# SAM9X75D1M device description
Architecture: ARM926EJ-S; Family: SAM9; Series: SAM9X7
Registers are 32-bit, read-write, reset 0x0 unless marked. A register's access mark holds for its fields unless they carry their own. Offsets are from the block's base; [hi:lo] are bit positions; {n}, {i} and the like mark numbered series.

## DSI — MIPI DSI Host
0x00 DSI_VERSION ro reset not defined — This register contains the version of the DSI host controller.
  [31:0] VERSION — This field indicates the version of the DWC_mipi_dsi_host.
0x04 DSI_PWR_UP reset not defined — This register controls the power up of the core.
  [0] SHUTDOWNZ — This bit configures the core either to power up or to reset. - 0: Reset - 1: Power-up
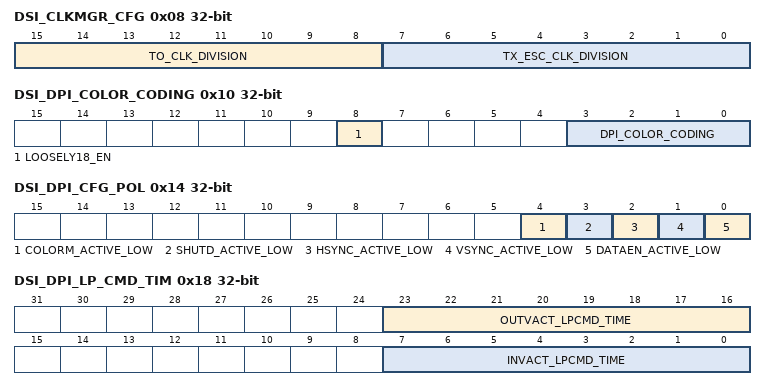
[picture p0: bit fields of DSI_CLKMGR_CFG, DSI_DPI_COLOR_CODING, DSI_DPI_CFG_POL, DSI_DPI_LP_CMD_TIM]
0x08 DSI_CLKMGR_CFG reset not defined — This register configures the factor for internal dividers to divide lanebyteclk for timeout purposes.
  [15:8] TO_CLK_DIVISION — This field indicates the division factor for the Time Out clock used as the timing unit in the configuration of HS to LP and LP to HS transition error.
  [7:0] TX_ESC_CLK_DIVISION — This field indicates the division factor for the TX Escape clock source (lanebyteclk). The values 0 and 1 stop the TX_ESC clock generation.
0x0C DSI_DPI_VCID reset not defined — This register configures the Virtual Channel ID for DPI traffic.
  [1:0] DPI_VCID — This field configures the DPI virtual channel id that is indexed to the Video mode packets.
0x10 DSI_DPI_COLOR_CODING reset not defined — This register configures DPI color coding.
  [8] LOOSELY18_EN — When set to 1, this bit activates loosely packed variant to 18-bit configurations.
  [3:0] DPI_COLOR_CODING — This field configures the DPI color coding as follows: - 0000: 16-bit configuration 1 - 0001: 16-bit configuration 2 - 0010: 16-bit configuration 3 - 0011: 18-bit configuration 1 - 0100: 18-bit configuration 2 - 0101: 24-bit - 0110: 20-bit YCbCr 4:2:2 loosely packed - 0111: 24-bit YCbCr 4:2:2 - 1000: 16-bit YCbCr 4:2:2 - 1001: 30-bit - 1010: 36-bit - 1011: 12-bit YCbCr 4:2:0 - 11xx: DSC24 compressed Data If the eDPI interface is chosen and currently works in the Command mode (cmd_video_mode = 1), then: - 0000: 16-bit configuration 1 - 0001: 16-bit configuration 2 - 0010: 16-bit configuration 3 - 0011: 18-bit configuration 1 - 0100: 18-bit configuration 2 - 0101-0111: 24-bit - 1Xxx: DSC24 compressed Data
0x14 DSI_DPI_CFG_POL reset not defined — This register configures the polarity of DPI signals.
  [4] COLORM_ACTIVE_LOW — When set to 1, this bit configures the color mode pin (dpicolorm) as active low.
  [3] SHUTD_ACTIVE_LOW — When set to 1, this bit configures the shutdown pin (dpishutdn) as active low.
  [2] HSYNC_ACTIVE_LOW — When set to 1, this bit configures the horizontal synchronism pin (dpihsync) as active low.
  [1] VSYNC_ACTIVE_LOW — When set to 1, this bit configures the vertical synchronism pin (dpivsync) as active low.
  [0] DATAEN_ACTIVE_LOW — When set to 1, this bit configures the data enable pin (dpidataen) as active low.
0x18 DSI_DPI_LP_CMD_TIM reset not defined — This register configures the timing for low-power commands sent while in video mode.
  [23:16] OUTVACT_LPCMD_TIME — This field is used for the transmission of commands in low-power mode. It defines the size, in bytes, of the largest packet that can fit in a line during the VSA, VBP, and VFP regions.
  [7:0] INVACT_LPCMD_TIME — This field is used for the transmission of commands in low-power mode. It defines the size, in bytes, of the largest packet that can fit in a line during the VACT region.
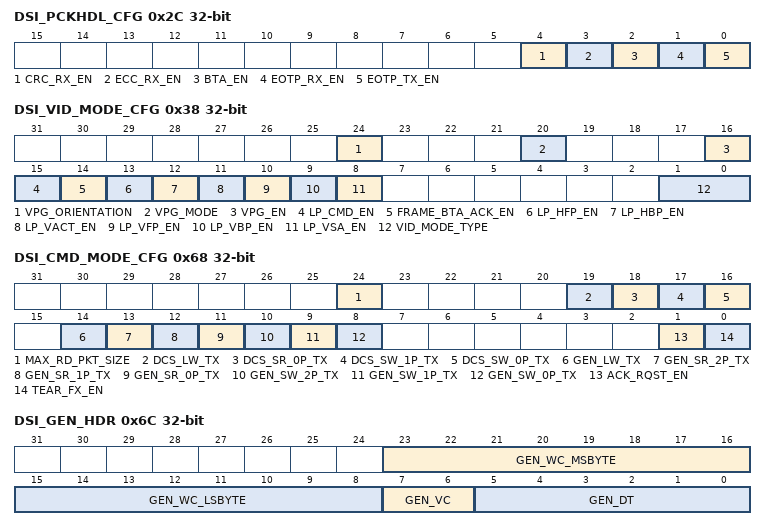
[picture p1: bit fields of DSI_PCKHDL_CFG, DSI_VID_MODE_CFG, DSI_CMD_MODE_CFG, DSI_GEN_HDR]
0x2C DSI_PCKHDL_CFG reset not defined — This register configures how EoTp, BTA, CRC and ECC are to be used, to meet peripheral's characteristics
  [4] CRC_RX_EN — When set to 1, this bit enables the CRC reception and error reporting.
  [3] ECC_RX_EN — When set to 1, this bit enables the ECC reception, error correction, and reporting.
  [2] BTA_EN — When set to 1, this bit enables the Bus Turn-Around (BTA) request.
  [1] EOTP_RX_EN — When set to 1, this bit enables the EoTp reception.
  [0] EOTP_TX_EN — When set to 1, this bit enables the EoTp transmission.
0x30 DSI_GEN_VCID reset not defined — This register configures the Virtual Channel ID of READ responses to store and return to Generic interface.
  [1:0] GEN_VCID_RX — This field indicates the Generic interface read-back virtual channel identification.
0x34 DSI_MODE_CFG reset not defined — This register configures the mode of operation between Video or Command Mode. (Commands can still be sent while in video mode.)
  [0] CMD_VIDEO_MODE — This bit configuers the operation mode: - 0: video mode - 1: command mode
0x38 DSI_VID_MODE_CFG reset not defined — This register configures several aspects of Video mode operation, the transmission mode, switching to Low-Power in the middle of a frame, enabling acknowledge and whether to send commands in Low-Power.
  [24] VPG_ORIENTATION — This field indicates the color bar orientation as follows: - 0: Vertical mode - 1: Horizontal mode
  [20] VPG_MODE — This field is to select the pattern: - 0: Color bar (horizontal or vertical) - 1: BERpattern (vertical only)
  [16] VPG_EN — When set to 1, this bit enables the video mode pattern generator.
  [15] LP_CMD_EN — When set to 1, this bit enables the command transmission only in low-power mode.
  [14] FRAME_BTA_ACK_EN — When set to 1, this bit enables the request for an acknowledge response at the end of a frame.
  [13] LP_HFP_EN — When set to 1, this bit enables the return to low-power inside the HFP period when timing allows.
  [12] LP_HBP_EN — When set to 1, this bit enables the return to low-power inside the HBP period when timing allows.
  [11] LP_VACT_EN — When set to 1, this bit enables the return to low-power inside the VACT period when timing allows.
  [10] LP_VFP_EN — When set to 1, this bit enables the return to low-power inside the VFP period when timing allows.
  [9] LP_VBP_EN — When set to 1, this bit enables the return to low-power inside the VBP period when timing allows.
  [8] LP_VSA_EN — When set to 1, this bit enables the return to low-power inside the VSA period when timing allows.
  [1:0] VID_MODE_TYPE — This field indicates the video mode transmission type as follows: - 00: Non-burst with sync pulses - 01: Non-burst with sync events - 10 and 11: Burst mode
0x3C DSI_VID_PKT_SIZE reset not defined — This register configures the video packet size.
  [13:0] VID_PKT_SIZE — This field configures the number of pixels in a single video packet. - For 18-bit not loosely packed data types, this number must be a multiple of 4. - For YCbCr data types, it must be a multiple of 2, as described in the DSI specification. - For DSC24, this field configures the number of Bytes. Note that when using slices (i.e chunks) the minimum size packet size must be 3.
0x40 DSI_VID_NUM_CHUNKS reset not defined — This register configures the number of chunks to use. The data in each chunk has the size provided by VID_PKT_SIZE.
  [12:0] VID_NUM_CHUNKS — This register configures the number of chunks to be transmitted during a Line period (a chunk is pair made of a video packet and a null packet). If set to 0 or 1, video line is still transmitted in a single packet. If set to 1 that packet is part of a chunk, meaning that a null packet follows it (if vid_null_size>0). Otherwise, multiple chunks are used to transmit each video line.
0x44 DSI_VID_NULL_SIZE reset not defined — This register configures the size of null packets.
  [12:0] VID_NULL_SIZE — This register configures the number of bytes inside a null packet. Setting to 0 disables null packets.
0x48 DSI_VID_HSA_TIME reset not defined — This register configures the video HSA time.
  [11:0] VID_HSA_TIME — This field configures the Horizontal Synchronism Active period in lane byte clock cycles.
0x4C DSI_VID_HBP_TIME reset not defined — This register configures the video HBP time.
  [11:0] VID_HBP_TIME — This field configures the Horizontal Back Porch period in lane byte clock cycles.
0x50 DSI_VID_HLINE_TIME reset not defined — This register configures the overall time for each video line.
  [14:0] VID_HLINE_TIME — This field configures the size of the total line time (HSA+HBP+HACT+HFP) counted in lane byte clock cycles.
0x54 DSI_VID_VSA_LINES reset not defined — This register configures the VSA period.
  [9:0] VSA_LINES — This field configures the Vertical Synchronism Active period measured in number of horizontal lines.
0x58 DSI_VID_VBP_LINES reset not defined — This register configures the VBP period.
  [9:0] VBP_LINES — This field configures the Vertical Back Porch period measured in number of horizontal lines.
0x5C DSI_VID_VFP_LINES reset not defined — This register configures the VFP period.
  [9:0] VFP_LINES — This field configures the Vertical Front Porch period measured in number of horizontal lines.
0x60 DSI_VID_VACTIVE_LINES reset not defined — This register configures the vertical resolution of video.
  [13:0] V_ACTIVE_LINES — This field configures the Vertical Active period measured in number of horizontal lines.
0x68 DSI_CMD_MODE_CFG reset not defined — This register configures several aspect of command mode operation, tearing effect, acknowledge for each packet and the speed mode to transmit each Data Type related to commands.
  [24] MAX_RD_PKT_SIZE — This bit configures the maximum read packet size command transmission type: - 0: High-speed - 1: Low-power
  [19] DCS_LW_TX — This bit configures the DCS long write packet command transmission type: - 0: High-speed - 1: Low-power
  [18] DCS_SR_0P_TX — This bit configures the DCS short read packet with zero parameter command transmission type: - 0: High-speed - 1: Low-power
  [17] DCS_SW_1P_TX — This bit configures the DCS short write packet with one parameter command transmission type: - 0: High-speed - 1: Low-power
  [16] DCS_SW_0P_TX — This bit configures the DCS short write packet with zero parameter command transmission type: - 0: High-speed - 1: Low-power
  [14] GEN_LW_TX — This bit configures the Generic long write packet command transmission type: - 0: High-speed - 1: Low-power
  [13] GEN_SR_2P_TX — This bit configures the Generic short read packet with two parameters command transmission type: - 0: High-speed - 1: Low-power
  [12] GEN_SR_1P_TX — This bit configures the Generic short read packet with one parameter command transmission type: - 0: High-speed - 1: Low-power
  [11] GEN_SR_0P_TX — This bit configures the Generic short read packet with zero parameter command transmission type: - 0: High-speed - 1: Low-power
  [10] GEN_SW_2P_TX — This bit configures the Generic short write packet with two parameters command transmission type: - 0: High-speed - 1: Low-power
  [9] GEN_SW_1P_TX — This bit configures the Generic short write packet with one parameter command transmission type: - 0: High-speed - 1: Low-power
  [8] GEN_SW_0P_TX — This bit configures the Generic short write packet with zero parameter command transmission type: - 0: High-speed - 1: Low-power
  [1] ACK_RQST_EN — When set to 1, this bit enables the acknowledge request after each packet transmission.
  [0] TEAR_FX_EN — When set to 1, this bit enables the tearing effect acknowledge request.
0x6C DSI_GEN_HDR reset not defined — This register sets the header for new packets sent using the Generic interface.
  [23:16] GEN_WC_MSBYTE — This field configures the most significant byte of the header packet's word count for long packets or data 1 for short packets.
  [15:8] GEN_WC_LSBYTE — This field configures the least significant byte of the header packet's Word count for long packets or data 0 for short packets.
  [7:6] GEN_VC — This field configures the Virtual Channel ID of the header packet.
  [5:0] GEN_DT — This field configures the packet Data Type of the header packet.
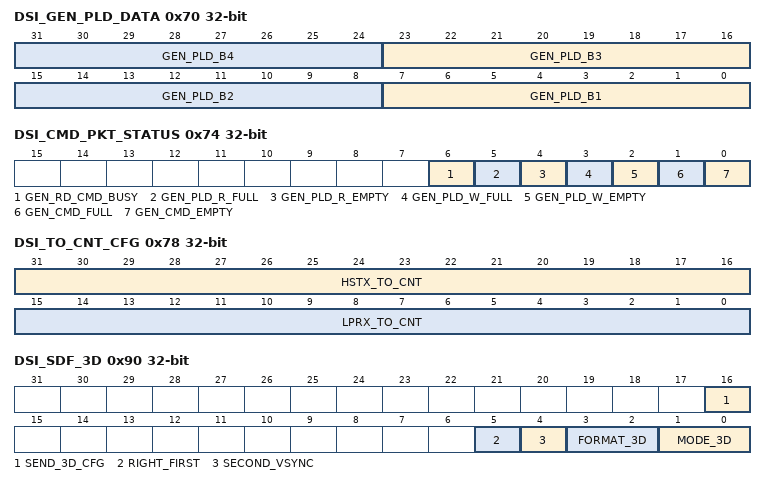
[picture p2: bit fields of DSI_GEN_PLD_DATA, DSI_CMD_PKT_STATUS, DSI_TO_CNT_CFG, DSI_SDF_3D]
0x70 DSI_GEN_PLD_DATA reset not defined — This register sets the payload for packets sent using the Generic interface and, when read, returns the contents of READ responses from the peripheral.
  [8n-1:8n-8] GEN_PLD_B{n} (n=1..4) — This field indicates byte {n} of the packet payload.
0x74 DSI_CMD_PKT_STATUS ro reset not defined — This register configures contains information about the status of FIFOs related to DBI and Generic interface.
  [6] GEN_RD_CMD_BUSY — This bit is set when a read command is issued and cleared when the entire response is stored in the FIFO for GENERIC interface.
  [5] GEN_PLD_R_FULL — This bit indicates the full status of the generic read payload FIFO.
  [4] GEN_PLD_R_EMPTY — This bit indicates the empty status of the generic read payload FIFO.
  [3] GEN_PLD_W_FULL — This bit indicates the full status of the generic write payload FIFO.
  [2] GEN_PLD_W_EMPTY — This bit indicates the empty status of the generic write payload FIFO.
  [1] GEN_CMD_FULL — This bit indicates the full status of the generic command FIFO.
  [0] GEN_CMD_EMPTY — This bit indicates the empty status of the generic command FIFO.
0x78 DSI_TO_CNT_CFG reset not defined — This register configures counters that trigger timeout errors. These are used to warn the system of a failure, through an interrupt, and restart the core in case of unexpected situations that cause deadlock conditions.
  [31:16] HSTX_TO_CNT — This field configures the timeout counter that triggers a high-speed transmission timeout contention detection (measured in TO_CLK_DIVISION cycles). If using non-burst mode and there is not sufficient time to switch from HS to LP and back in the period which is from one line data finishing to the next line sync start, the DSI link will return LP state once per frame, then you should configure the TO_CLK_DIVISION and hstx_to_cnt to satisfy the formula below: hstx_to_cnt * lanebyteclkperiod * TO_CLK_DIVISION >= the time of one FRAME data transmission * (1 + 10%) In burst mode, RGB pixel packets are time-compressed, leaving more time during a scan line. So if in burst mode and there is sufficient time to switch from HS to LP and back in the period of time from one line data finishing to the next line sync start, the DSI link can return LP mode and back in this time interval to save power. If you choose so, you should configure the TO_CLK_DIVISION and hstx_to_cnt to satisfy the formula below: hstx_to_cnt * lanebyteclkperiod * TO_CLK_DIVISION >= the time of one LINE data transmission * (1 + 10%)
  [15:0] LPRX_TO_CNT — This field configures the timeout counter that triggers a low-power reception timeout contention detection (measured in TO_CLK_DIVISION cycles).
0x7C DSI_HS_RD_TO_CNT reset not defined — This register configures the Peripheral Response timeout after High-Speed Read operations.
  [15:0] HS_RD_TO_CNT — This field sets a period for which DWC_mipi_dsi_host keeps the link still, after sending a High-Speed Read operation. This period is measured in cycles of lanebyteclk, starts to count when the D-PHY enters stop state and causes no interrupts.
0x80 DSI_LP_RD_TO_CNT reset not defined — This register configures the Peripheral Response timeout after Low-Power Read operations.
  [15:0] LP_RD_TO_CNT — This field sets a period for which DWC_mipi_dsi_host keeps the link still, after sending a Low-Power Read operation. This period is measured in cycles of lanebyteclk, starts to count when the D-PHY enters stop state and causes no interrupts.
0x84 DSI_HS_WR_TO_CNT reset not defined — This register configures the Peripheral Response timeout after High-Speed Write operations.
  [15:0] HS_WR_TO_CNT — This field sets a period for which DWC_mipi_dsi_host keeps the link still, after sending a High-Speed Write operation. This period is measured in cycles of lanebyteclk, starts to count when the D-PHY enters stop state and causes no interrupts.
0x88 DSI_LP_WR_TO_CNT reset not defined — This register configures the Peripheral Response timeout after Low-Power Write operations.
  [15:0] LP_WR_TO_CNT — This field sets a period for which DWC_mipi_dsi_host keeps the link still, after sending a Low-Power Write operation. This period is measured in cycles of lanebyteclk, starts to count when the D-PHY enters stop state and causes no interrupts.
0x8C DSI_BTA_TO_CNT reset not defined — This register configures the Peripheral Response timeout after Bus Turnaround completion.
  [15:0] BTA_TO_CNT — This field sets a period for which DWC_mipi_dsi_host keeps the link still, after completing a Bus Turnaround. This period is measured in cycles of lanebyteclk, starts to count when the D-PHY enters stop state and causes no interrupts.
0x90 DSI_SDF_3D reset not defined — This register stores 3D control information for VSS packets in video mode.
  [16] SEND_3D_CFG — When set, causes the next VSS packet to include 3D control payload in every VSS packet.
  [5] RIGHT_FIRST — This bit defines the left/right order: - 0: left eye is sent first, then right eye - 1: right eye data is sent first, then left eye
  [4] SECOND_VSYNC — This field defines whether there is a second VSYNC pulse between Left and Right Images, when 3D Image Format is Frame-based: - 0: No sync pulses between left and right data. - 1: Sync pulse (HSYNC, VSYNC, blanking) between left and right data.
  [3:2] FORMAT_3D — This field defines 3D Image Format: - 00: Line (alternating lines of left and right data). - 01: Frame (alternating frames of left and right data). - 10: Pixel (alternating pixels of left and right data). - 11: Reserved
  [1:0] MODE_3D — This field defines 3D Mode On/Off and Display Orientation: - 00: 3D Mode Off (2D Mode On). - 01: 3D Mode On, Portrait Orientation. - 10: 3D Mode On, Landscape Orientation. - 11: Reserved.
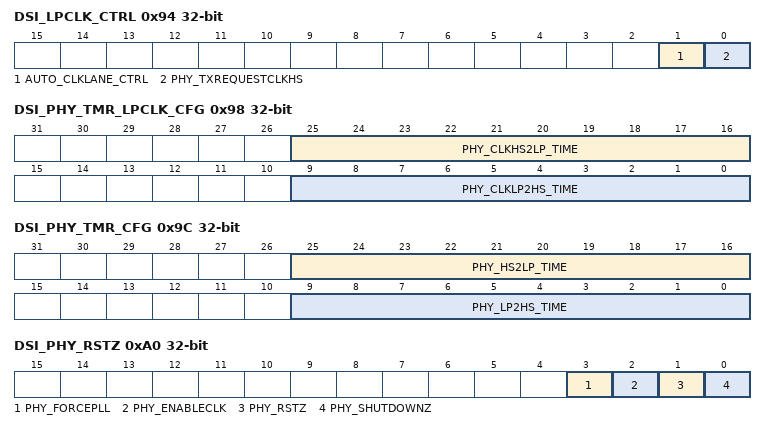
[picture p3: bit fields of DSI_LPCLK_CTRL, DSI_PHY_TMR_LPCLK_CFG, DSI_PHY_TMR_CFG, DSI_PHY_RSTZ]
0x94 DSI_LPCLK_CTRL reset not defined — This register configures the possibility for using non continuous clock in the clock lane.
  [1] AUTO_CLKLANE_CTRL — This bit enables the automatic mechanism to stop providing clock in the clock lane when time allows.
  [0] PHY_TXREQUESTCLKHS — This bit controls the D-PHY PPI txrequestclkhs signal.
0x98 DSI_PHY_TMR_LPCLK_CFG reset not defined — This register sets the time that DWC_mipi_dsi_host assumes in calculations for the clock lane to switch between High-Speed and Low-Power.
  [25:16] PHY_CLKHS2LP_TIME — This field configures the maximum time that the D-PHY clock lane takes to go from high-speed to low-power transmission measured in lane byte clock cycles.
  [9:0] PHY_CLKLP2HS_TIME — This field configures the maximum time that the D-PHY clock lane takes to go from low-power to high-speed transmission measured in lane byte clock cycles.
0x9C DSI_PHY_TMR_CFG reset not defined — This register sets the time that DWC_mipi_dsi_host assumes in calculations for the data lanes to switch between High-Speed and Low-Power.
  [25:16] PHY_HS2LP_TIME — This field configures the maximum time that the D-PHY data lanes take to go from high-speed to low-power transmission measured in lane byte clock cycles.
  [9:0] PHY_LP2HS_TIME — This field configures the maximum time that the D-PHY data lanes take to go from low-power to high-speed transmission measured in lane byte clock cycles.
0xA0 DSI_PHY_RSTZ reset not defined — This register controls resets and the PLL of the D-PHY.
  [3] PHY_FORCEPLL — When the D-PHY is in ULPS, this bit enables the D-PHY PLL.
  [2] PHY_ENABLECLK — When set to 1, this bit enables the D-PHY Clock Lane Module.
  [1] PHY_RSTZ — When set to 0, this bit places the digital section of the D-PHY in the reset state.
  [0] PHY_SHUTDOWNZ — When set to 0, this bit places the complete D-PHY macro in power-down state.
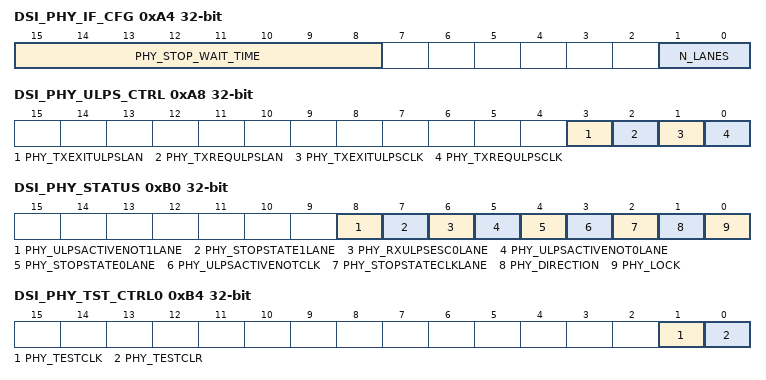
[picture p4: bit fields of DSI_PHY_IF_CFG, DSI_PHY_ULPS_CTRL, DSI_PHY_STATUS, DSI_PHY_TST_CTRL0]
0xA4 DSI_PHY_IF_CFG reset not defined — This register configures the number of active lanes and the minimum time to remain in stop state.
  [15:8] PHY_STOP_WAIT_TIME — This field configures the minimum wait period to request a highspeed transmission after the Stop state.
  [1:0] N_LANES — This field configures the number of active data lanes: - 00: One data lane (ane 0) - 01: Two data lanes (lanes 0 and 1) - 10: Three data lanes (lanes 0, 1, and 2) - 11: Four data lanes (lanes 0, 1, 2, and 3)
0xA8 DSI_PHY_ULPS_CTRL reset not defined — This register configures entering and leaving ULPS in the D-PHY.
  [3] PHY_TXEXITULPSLAN — ULPS mode Exit on all active data lanes.
  [2] PHY_TXREQULPSLAN — ULPS mode Request on all active data lanes.
  [1] PHY_TXEXITULPSCLK — ULPS mode Exit on clock lane.
  [0] PHY_TXREQULPSCLK — ULPS mode Request on clock lane.
0xAC DSI_PHY_TX_TRIGGERS reset not defined — This register configures the pins that activate triggers in the D-PHY.
  [3:0] PHY_TX_TRIGGERS — This field controls the trigger transmissions.
0xB0 DSI_PHY_STATUS ro reset not defined — This register contains information about the status of the D-PHY.
  [8] PHY_ULPSACTIVENOT1LANE — This bit indicates the status of ulpsactivenot1lane D-PHY signal.
  [7] PHY_STOPSTATE1LANE — This bit indicates the status of phystopstate1lane D-PHY signal.
  [6] PHY_RXULPSESC0LANE — This bit indicates the status of rxulpsesc0lane D-PHY signal.
  [5] PHY_ULPSACTIVENOT0LANE — This bit indicates the status of ulpsactivenot0lane D-PHY signal.
  [4] PHY_STOPSTATE0LANE — This bit indicates the status of phystopstate0lane D-PHY signal.
  [3] PHY_ULPSACTIVENOTCLK — This bit indicates the status of phyulpsactivenotclk D-PHY signal.
  [2] PHY_STOPSTATECLKLANE — This bit indicates the status of phystopstateclklane D-PHY signal.
  [1] PHY_DIRECTION — This bit indicates the status of phydirection D-PHY signal.
  [0] PHY_LOCK — This bit indicates the status of phylock D-PHY signal.
0xB4 DSI_PHY_TST_CTRL0 reset not defined — This register controls clock and clear pins of the D-PHY vendor specific interface.
  [1] PHY_TESTCLK — This bit is used to clock the TESTDIN bus into the D-PHY.
  [0] PHY_TESTCLR — PHY test interface clear (active high).
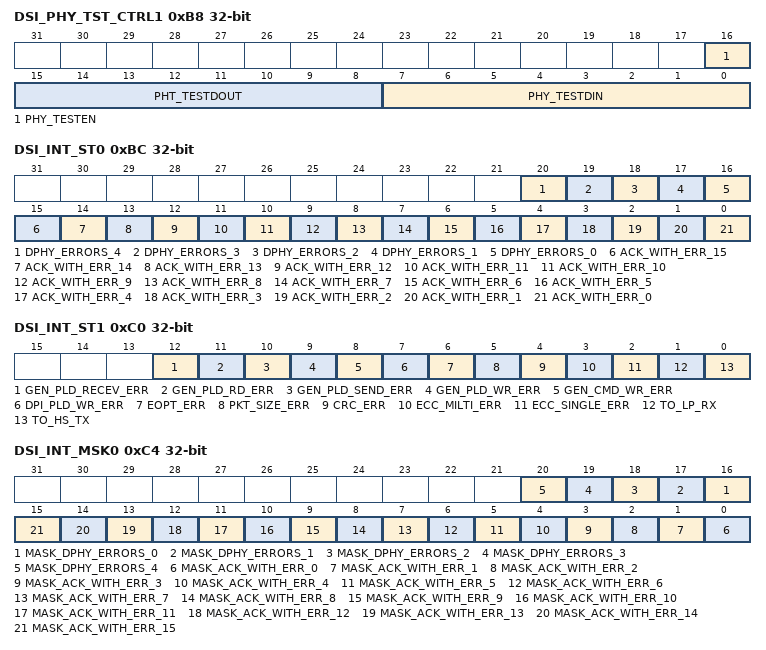
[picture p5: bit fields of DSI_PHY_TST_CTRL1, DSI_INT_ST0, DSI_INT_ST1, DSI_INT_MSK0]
0xB8 DSI_PHY_TST_CTRL1 reset not defined — This register controls data and enable pins of the D-PHY vendor specific interface.
  [16] PHY_TESTEN — PHY test interface operation selector: 1: the address write operation is set on the falling edge of the testclk signal. 0: the data write operation is set on the rising edge of the testclk signal.
  [15:8] PHT_TESTDOUT — PHY output 8-bit data bus for read-back and internal probing functionalities.
  [7:0] PHY_TESTDIN — PHY test interface input 8-bit data bus for internal register programming and test functionalities access.
0xBC DSI_INT_ST0 ro reset not defined — This register contains the status of interrupt sources from acknowledge reports and the D-PHY.
  [20] DPHY_ERRORS_4 — This bit indicates LP1 contention error ErrContentionLP1 from Lane 0.
  [19] DPHY_ERRORS_3 — This bit indicates LP0 contention error ErrContentionLP0 from Lane 0.
  [18] DPHY_ERRORS_2 — This bit indicates control error ErrControl from Lane 0.
  [17] DPHY_ERRORS_1 — This bit indicates ErrSyncEsc low-power data transmission synchronization error from Lane 0.
  [16] DPHY_ERRORS_0 — This bit indicates ErrEsc escape entry error from Lane 0.
  [15] ACK_WITH_ERR_15 — This bit retrieves the DSI protocol violation from the Acknowledge error report.
  [14] ACK_WITH_ERR_14 — This bit retrieves the reserved (specific to device) from the Acknowledge error report.
  [13] ACK_WITH_ERR_13 — This bit retrieves the invalid transmission length from the Acknowledge error report.
  [12] ACK_WITH_ERR_12 — This bit retrieves the DSI VC ID Invalid from the Acknowledge error report.
  [11] ACK_WITH_ERR_11 — This bit retrieves the not recognized DSI data type from the Acknowledge error report.
  [10] ACK_WITH_ERR_10 — This bit retrieves the checksum error (long packet only) from the Acknowledge error report.
  [9] ACK_WITH_ERR_9 — This bit retrieves the ECC error, multi-bit (detected, not corrected) from the Acknowledge error report.
  [8] ACK_WITH_ERR_8 — This bit retrieves the ECC error, single-bit (detected and corrected) from the Acknowledge error report.
  [7] ACK_WITH_ERR_7 — This bit retrieves the reserved (specific to device) from the acknowledge error report.
  [6] ACK_WITH_ERR_6 — This bit retrieves the False Control error from the Acknowledge error report.
  [5] ACK_WITH_ERR_5 — This bit retrieves the Peripheral Timeout error from the Acknowledge error report.
  [4] ACK_WITH_ERR_4 — This bit retrieves the LP Transmit Sync error from the Acknowledge error report.
  [3] ACK_WITH_ERR_3 — This bit retrieves the Escape Mode Entry Command error from the Acknowledge error report.
  [2] ACK_WITH_ERR_2 — This bit retrieves the EoT Sync error from the Acknowledge error report.
  [1] ACK_WITH_ERR_1 — This bit retrieves the SoT Sync error from the Acknowledge error report.
  [0] ACK_WITH_ERR_0 — This bit retrieves the SoT error from the Acknowledge error report.
0xC0 DSI_INT_ST1 ro reset not defined — This register contains the status of interrupt sources related to timeouts, ECC, CRC, packet size, EoTp, Generic and DBI interfaces.
  [12] GEN_PLD_RECEV_ERR — This bit indicates that during a generic interface packet read back, the payload FIFO becomes full and the received data is corrupted.
  [11] GEN_PLD_RD_ERR — This bit indicates that during a DCS read data, the payload FIFO becomes empty and the data sent to the interface is corrupted.
  [10] GEN_PLD_SEND_ERR — This bit indicates that during a Generic interface packet build, the payload FIFO becomes empty and corrupt data is sent.
  [9] GEN_PLD_WR_ERR — This bit indicates that the system tried to write a payload data through the Generic interface and the FIFO is full. Therefore, the payload is not written.
  [8] GEN_CMD_WR_ERR — This bit indicates that the system tried to write a command through the Generic interface and the FIFO is full. Therefore, the command is not written.
  [7] DPI_PLD_WR_ERR — This bit indicates that during a DPI pixel line storage, the payload FIFO becomes full and the data stored is corrupted.
  [6] EOPT_ERR — This bit indicates that the EoTp packet has not been received at the end of the incoming peripheral transmission.
  [5] PKT_SIZE_ERR — This bit indicates that the packet size error has been detected during the packet reception.
  [4] CRC_ERR — This bit indicates that the CRC error has been detected in the received packet payload.
  [3] ECC_MILTI_ERR — This bit indicates that the ECC multiple error has been detected in a received packet.
  [2] ECC_SINGLE_ERR — This bit indicates that the ECC single error has been detected and corrected in a received packet.
  [1] TO_LP_RX — This bit indicates that the low-power reception timeout counter reached the end and contention has been detected.
  [0] TO_HS_TX — This bit indicates that the high-speed transmission timeout counter reached the end and contention has been detected.
0xC4 DSI_INT_MSK0 reset not defined — This register configures masks for the sources of interrupts that affect the INT_ST0 register. Write 1 to Un-mask each error report.
  [n+16] MASK_DPHY_ERRORS_{n} (n=0..4) — Mask for dphy_errors_{n}
  [n] MASK_ACK_WITH_ERR_{n} (n=0..15) — Mask for ack_with_err_{n}
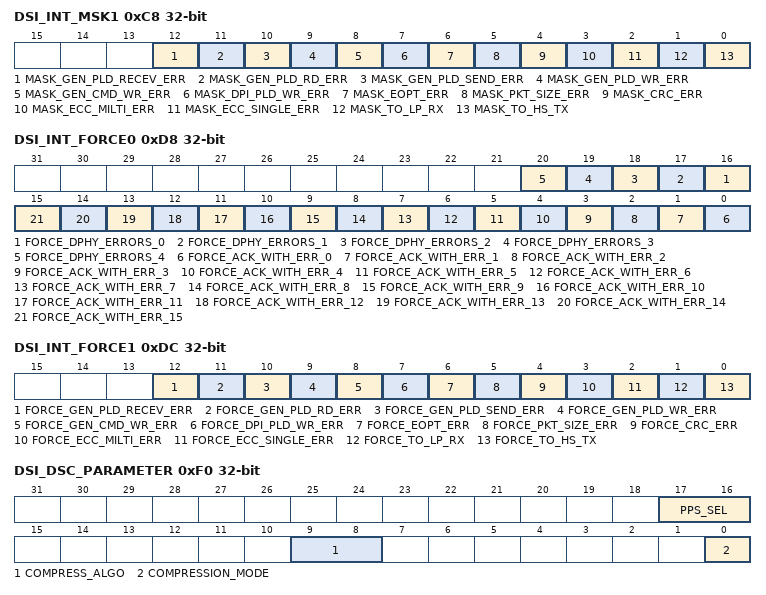
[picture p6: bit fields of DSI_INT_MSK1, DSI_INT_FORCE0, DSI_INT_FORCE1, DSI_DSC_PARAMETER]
0xC8 DSI_INT_MSK1 reset not defined — This register configures masks for the sources of interrupts that affect the INT_ST1 register.
  [12] MASK_GEN_PLD_RECEV_ERR — Mask for gen_pld_recev_err
  [11] MASK_GEN_PLD_RD_ERR — Mask for gen_pld_rd_err
  [10] MASK_GEN_PLD_SEND_ERR — Mask for gen_pld_send_err
  [9] MASK_GEN_PLD_WR_ERR — Mask for gen_pld_wr_err
  [8] MASK_GEN_CMD_WR_ERR — Mask for gen_cmd_wr_err
  [7] MASK_DPI_PLD_WR_ERR — Mask for dpi_pld_wr_err
  [6] MASK_EOPT_ERR — Mask for eopt_err
  [5] MASK_PKT_SIZE_ERR — Mask for pkt_size_err
  [4] MASK_CRC_ERR — Mask for crc_err
  [3] MASK_ECC_MILTI_ERR — Mask for ecc_milti_err
  [2] MASK_ECC_SINGLE_ERR — Mask for ecc_single_err
  [1] MASK_TO_LP_RX — Mask for to_lp_rx
  [0] MASK_TO_HS_TX — Mask for to_hs_tx
0xCC DSI_PHY_CAL reset not defined — This register controls the skew calibration of D-PHY.
  [0] TXSKEWCALHS — High-speed skew calibration is started when txskewcalhs is set high (assuming that PHY is in Stop state)
0xD8 DSI_INT_FORCE0 wo reset not defined — This register forces that affect the INT_ST0 register.
  [n+16] FORCE_DPHY_ERRORS_{n} (n=0..4), [n] FORCE_ACK_WITH_ERR_{n} (n=0..15)
0xDC DSI_INT_FORCE1 wo reset not defined — This register forces interrupts that affect the INT_ST1 register.
  [12] FORCE_GEN_PLD_RECEV_ERR, [11] FORCE_GEN_PLD_RD_ERR, [10] FORCE_GEN_PLD_SEND_ERR, [9] FORCE_GEN_PLD_WR_ERR, [8] FORCE_GEN_CMD_WR_ERR, [7] FORCE_DPI_PLD_WR_ERR, [6] FORCE_EOPT_ERR, [5] FORCE_PKT_SIZE_ERR, [4] FORCE_CRC_ERR, [3] FORCE_ECC_MILTI_ERR, [2] FORCE_ECC_SINGLE_ERR, [1] FORCE_TO_LP_RX, [0] FORCE_TO_HS_TX
0xF0 DSI_DSC_PARAMETER reset not defined — This register configures Display Stream Compression
  [17:16] PPS_SEL — This field indicates the PPS selector: - 00 = PPS Table 1 - 01 = PPS Table 2 - 10 = PPS Table 3 - 11 = PPS Table 4
  [9:8] COMPRESS_ALGO — This field indicates the algorithm identifier: - 00 = VESA DSC Standard 1.1 - 11 = vendor-specific algorithm - 01 and 10 = reserved, not used
  [0] COMPRESSION_MODE — When set to 1, this bit enables the compression mode.
0xF4 DSI_PHY_TMR_RD_CFG reset not defined — This register configures times related to PHY to perform some operations in lane byte clock cycles.
  [14:0] MAX_RD_TIME — This field configures the maximum time required to perform a read command in lane byte clock cycles. This register can only be modified when no read command is in progress.
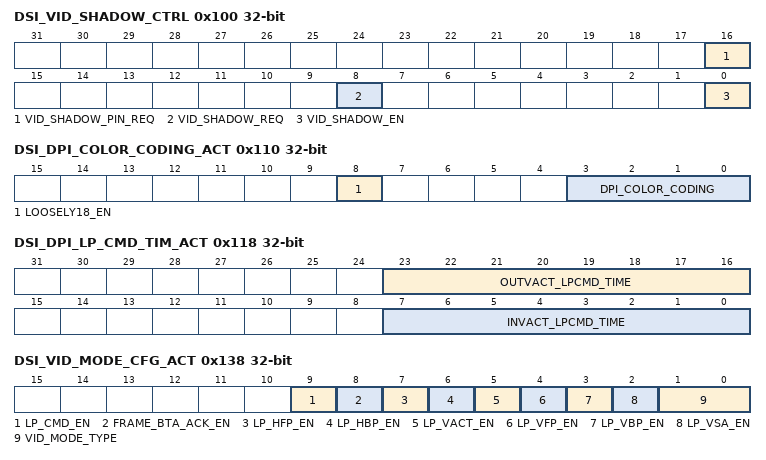
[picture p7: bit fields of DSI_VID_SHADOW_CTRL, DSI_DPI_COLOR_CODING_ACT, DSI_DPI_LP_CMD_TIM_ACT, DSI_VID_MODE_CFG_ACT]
0x100 DSI_VID_SHADOW_CTRL reset not defined — This register controls dpi shadow feature
  [16] VID_SHADOW_PIN_REQ — When set to 1, the video request is done by external pin. In this mode vid_shadow_req is ignored.
  [8] VID_SHADOW_REQ — When set to 1, this bit request that the dpi registers from regbank are copied to the auxiliary registers. When the request is completed this bit is auto clear.
  [0] VID_SHADOW_EN — When set to 1, DPI receives the active configuration from the auxiliary registers. When the feature is set at the same time than vid_shadow_req the auxiliary registers are automatically updated.
0x10C DSI_DPI_VCID_ACT ro reset not defined — This register holds the value that controller is using for DPI_VCID.
  [1:0] DPI_VCID — This field specifies the DPI virtual channel id that is indexed to the Video mode packets.
0x110 DSI_DPI_COLOR_CODING_ACT ro reset not defined — This register holds the value that controller is using for DPI_COLOR_CODING.
  [8] LOOSELY18_EN — When 1, this bit activates loosely packed variant to 18-bit configurations.
  [3:0] DPI_COLOR_CODING — This field specifies the DPI color coding as follows: - 0000: 16-bit configuration 1 - 0001: 16-bit configuration 2 - 0010: 16-bit configuration 3 - 0011: 18-bit configuration 1 - 0100: 18-bit configuration 2 - 0101: 24-bit - 0110: 20-bit YCbCr 4:2:2 loosely packed - 0111: 24-bit YCbCr 4:2:2 - 1000: 16-bit YCbCr 4:2:2 - 1001: 30-bit - 1010: 36-bit - 1011: 12-bit YCbCr 4:2:0 - 11xx: DSC24 compressed Data If the eDPI interface is chosen and currently works in the Command mode (cmd_video_mode = 1), then: - 0000: 16-bit configuration 1 - 0001: 16-bit configuration 2 - 0010: 16-bit configuration 3 - 0011: 18-bit configuration 1 - 0100: 18-bit configuration 2 - 0101-0111: 24-bit - 1Xxx: DSC24 compressed Data
0x118 DSI_DPI_LP_CMD_TIM_ACT ro reset not defined — This register holds the value that controller is using for DPI_LP_CMD_TIM.
  [23:16] OUTVACT_LPCMD_TIME — This field is used for the transmission of commands in low-power mode. It specifies the size, in bytes, of the largest packet that can fit in a line during the VSA, VBP, and VFP regions.
  [7:0] INVACT_LPCMD_TIME — This field is used for the transmission of commands in low-power mode. It specifies the size, in bytes, of the largest packet that can fit in a line during the VACT region.
0x138 DSI_VID_MODE_CFG_ACT ro reset not defined — This register holds the value that controller is using for VID_MODE_CFG.
  [9] LP_CMD_EN — When 1, this bit enables the command transmission only in low-power mode.
  [8] FRAME_BTA_ACK_EN — When 1, this bit enables the request for an acknowledge response at the end of a frame.
  [7] LP_HFP_EN — When 1, this bit enables the return to low-power inside the HFP period when timing allows.
  [6] LP_HBP_EN — When 1, this bit enables the return to low-power inside the HBP period when timing allows.
  [5] LP_VACT_EN — When 1, this bit enables the return to low-power inside the VACT period when timing allows.
  [4] LP_VFP_EN — When 1, this bit enables the return to low-power inside the VFP period when timing allows.
  [3] LP_VBP_EN — When 1, this bit enables the return to low-power inside the VBP period when timing allows.
  [2] LP_VSA_EN — When 1, this bit enables the return to low-power inside the VSA period when timing allows.
  [1:0] VID_MODE_TYPE — This field specifies the video mode transmission type as follows: 00: Non-burst with sync pulses 01: Non-burst with sync events 10 and 11: Burst mode
0x13C DSI_VID_PKT_SIZE_ACT ro reset not defined — This register holds the value that controller is using for VID_PKT_SIZE.
  [13:0] VID_PKT_SIZE — This field specifies the number of pixels in a single video packet. For 18-bit not loosely packed this number must be a multiple of 4 and YCbCr Data Types, it must be a multiple of 2, as described in DSI specification.
0x140 DSI_VID_NUM_CHUNKS_ACT ro reset not defined — This register holds the value that controller is using for VID_NUM_CHUNKS.
  [12:0] VID_NUM_CHUNKS — This register specifies the number of chunks to be transmitted during a Line period (a chunk is pair made of a video packet and a null packet). If set to 0 or 1, video line is still transmitted in a single packet. If set to 1 that packet is part of a chunk, meaning that a null packet follows it (if vid_null_size>0). Otherwise, multiple chunks are used to transmit each video line.
0x144 DSI_VID_NULL_SIZE_ACT ro reset not defined — This register holds the value that controller is using for VID_NULL_SIZE.
  [12:0] VID_NULL_SIZE — This register specifies the number of bytes inside a null packet. Setting to 0 disables null packets.
0x148 DSI_VID_HSA_TIME_ACT ro reset not defined — This register holds the value that controller is using for VID_HSA_TIME.
  [11:0] VID_HSA_TIME — This field specifies the Horizontal Synchronism Active period in lane byte clock cycles.
0x14C DSI_VID_HBP_TIME_ACT ro reset not defined — This register holds the value that controller is using for VID_HBP_TIME.
  [11:0] VID_HBP_TIME — This field specifies the Horizontal Back Porch period in lane byte clock cycles.
0x150 DSI_VID_HLINE_TIME_ACT ro reset not defined — This register holds the value that controller is using for VID_HLINE_TIME.
  [14:0] VID_HLINE_TIME — This field specifies the size of the total line time (HSA+HBP+HACT+HFP) counted in lane byte clock cycles.
0x154 DSI_VID_VSA_LINES_ACT ro reset not defined — This register holds the value that controller is using for VID_VSA_LINES.
  [9:0] VSA_LINES — This field specifies the Vertical Synchronism Active period measured in number of horizontal lines.
0x158 DSI_VID_VBP_LINES_ACT ro reset not defined — This register holds the value that controller is using for VID_VBP_LINES.
  [9:0] VBP_LINES — This field specifies the Vertical Back Porch period measured in number of horizontal lines.
0x15C DSI_VID_VFP_LINES_ACT ro reset not defined — This register holds the value that controller is using for VID_VFP_LINES.
  [9:0] VFP_LINES — This field specifies the Vertical Front Porch period measured in number of horizontal lines.
0x160 DSI_VID_VACTIVE_LINES_ACT ro reset not defined — This register holds the value that controller is using for VID_VACTIVE_LINES.
  [13:0] V_ACTIVE_LINES — This field specifies the Vertical Active period measured in number of horizontal lines.
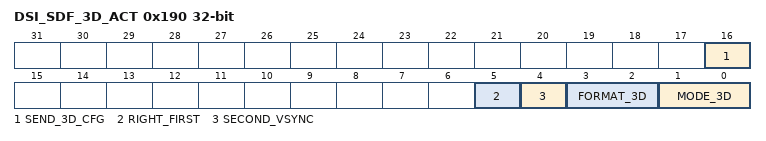
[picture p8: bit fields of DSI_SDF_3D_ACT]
0x190 DSI_SDF_3D_ACT ro reset not defined — This register holds the value that controller is using for SDF_3D.
  [16] SEND_3D_CFG — When set, causes the next VSS packet to include 3D control payload in every VSS packet.
  [5] RIGHT_FIRST — This bit specifies the left/right order: - 0: left eye is sent first, then right eye - 1: right eye data is sent first, then left eye
  [4] SECOND_VSYNC — This field specifies whether there is a second VSYNC pulse between Left and Right Images, when 3D Image Format is Frame-based: - 0: No sync pulses between left and right data. - 1: Sync pulse (HSYNC, VSYNC, blanking) between left and right data.
  [3:2] FORMAT_3D — This field specifies 3D Image Format: - 00: Line (alternating lines of left and right data). - 01: Frame (alternating frames of left and right data). - 10: Pixel (alternating pixels of left and right data). - 11: Reserved
  [1:0] MODE_3D — This field specifies 3D Mode On/Off and Display Orientation: - 00: 3D Mode Off (2D Mode On). - 01: 3D Mode On, Portrait Orientation. - 10: 3D Mode On, Landscape Orientation. - 11: Reserved.

## Notices in the file
Copyright (c) 2021 Microchip Technology Inc.
SPDX-License-Identifier: Apache-2.0
Licensed under the Apache License, Version 2.0 (the "License");
you may not use this file except in compliance with the License.
You may obtain a copy of the License at
http://www.apache.org/licenses/LICENSE-2.0
Unless required by applicable law or agreed to in writing, software
distributed under the License is distributed on an "AS IS" BASIS,
WITHOUT WARRANTIES OR CONDITIONS OF ANY KIND, either express or implied.
See the License for the specific language governing permissions and
limitations under the License.
